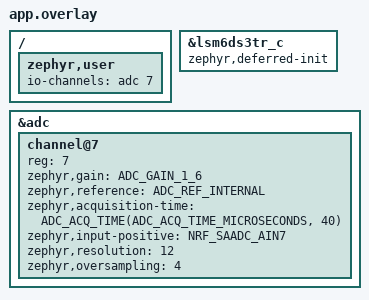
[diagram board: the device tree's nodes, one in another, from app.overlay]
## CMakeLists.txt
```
# Lift tracker D1 logger firmware
cmake_minimum_required(VERSION 3.20.0)
find_package(Zephyr REQUIRED HINTS $ENV{ZEPHYR_BASE})
project(lift_logger)

target_sources(app PRIVATE src/main.c src/storage.c src/ble.c)
```

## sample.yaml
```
sample:
  name: Lift tracker D1 logger
tests:
  lift.logger:
    platform_allow: xiao_ble/nrf52840/sense
    tags: sensors
```

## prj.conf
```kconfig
# ---- IMU: LSM6DS3TR-C (uses Zephyr's LSM6DSL driver) ----
CONFIG_SENSOR=y
CONFIG_LSM6DSL=y
CONFIG_LSM6DSL_TRIGGER_NONE=y
# 208 Hz output data rate for both sensors (the logger samples at 100 Hz)
CONFIG_LSM6DSL_ACCEL_ODR=5
CONFIG_LSM6DSL_GYRO_ODR=5
# +/-8 g and +/-1000 deg/s: headroom for fast reps without clipping
CONFIG_LSM6DSL_ACCEL_FS=8
CONFIG_LSM6DSL_GYRO_FS=1000

# ---- 2 MB external QSPI flash for recordings ----
CONFIG_FLASH=y

# ---- LEDs ----
CONFIG_GPIO=y

# ---- Shell + logs over the USB serial port ----
CONFIG_SHELL=y
CONFIG_SHELL_STACK_SIZE=4096
CONFIG_SHELL_CMD_BUFF_SIZE=128
CONFIG_LOG=y
CONFIG_MAIN_STACK_SIZE=2048
# Plain text output so the laptop script can parse it
CONFIG_SHELL_VT100_COLORS=n
CONFIG_CDC_ACM_SERIAL_PRODUCT_STRING="Lift Tracker Logger"

# ---- rec dfu: reboot into the UF2 bootloader ----
CONFIG_REBOOT=y

# ---- battery voltage (rec batt) ----
CONFIG_ADC=y

# ---- Bluetooth LE link to the phone app (src/ble.c) ----
CONFIG_BT=y
CONFIG_BT_PERIPHERAL=y
CONFIG_BT_DEVICE_NAME="LiftPod"
CONFIG_BT_MAX_CONN=1
# Ask the phone for a 15-30 ms connection interval: the live stream is 25 Hz
CONFIG_BT_PERIPHERAL_PREF_MIN_INT=12
CONFIG_BT_PERIPHERAL_PREF_MAX_INT=24
CONFIG_BT_PERIPHERAL_PREF_LATENCY=0
CONFIG_BT_PERIPHERAL_PREF_TIMEOUT=400
CONFIG_BT_GAP_AUTO_UPDATE_CONN_PARAMS=y
```

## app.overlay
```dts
/* The XIAO Sense powers its IMU through a GPIO-controlled switch
 * (lsm6ds3tr-c-en, 3 ms startup delay in the board file). The IMU can
 * need longer than that after power-up, and if Zephyr probes it too early
 * the driver gives up for good (device shows DISABLED). So skip the boot-time
 * init and start it from the firmware after a proper delay, with retries. */
&lsm6ds3tr_c {
	zephyr,deferred-init;
};

/* Battery voltage: the XIAO divides BAT through 1 M / 510 k onto P0.31
 * (AIN7). The divider's low side is P0.14, which the firmware drives low
 * to switch it on (and keeps low: Seeed warns against driving it high while
 * charging). */
/ {
	zephyr,user {
		io-channels = <&adc 7>;
	};
};

&adc {
	#address-cells = <1>;
	#size-cells = <0>;

	channel@7 {
		reg = <7>;
		zephyr,gain = "ADC_GAIN_1_6";
		zephyr,reference = "ADC_REF_INTERNAL";
		zephyr,acquisition-time = <ADC_ACQ_TIME(ADC_ACQ_TIME_MICROSECONDS, 40)>;
		zephyr,input-positive = <NRF_SAADC_AIN7>;   /* P0.31 */
		zephyr,resolution = <12>;
		zephyr,oversampling = <4>;
	};
};
```

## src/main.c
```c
/*
 * Lift tracker - D1 logger firmware (Seeed XIAO nRF52840 Sense)
 *
 * What it does
 *   - Reads the on-board IMU (LSM6DS3TR-C: accelerometer + gyroscope)
 *     at SAMPLE_HZ, all the time.
 *   - On battery (no USB cable): starts a recording automatically when you
 *     start moving, and stops after STOP_STILL_S seconds of stillness.
 *     So each set becomes its own recording, with no button to press.
 *     The last PRETRIGGER_S seconds before the motion are kept too, so the
 *     first rep is never cut off.
 *   - With the phone app (Bluetooth): the app starts and stops each set
 *     and labels it (exercise, weight, set number), and gets a live IMU
 *     stream for its rep counter. Once the app has connected, motion-
 *     triggered recording is off until the pod reboots, so walking
 *     between sets is never recorded. See ble.h.
 *   - On USB: never records by itself. A shell on the USB serial port lets
 *     the laptop list, dump (as CSV) and erase recordings, or start and
 *     stop a recording by hand for desk tests.
 *
 * LED
 *   green blink (fast)      recording
 *   green blip every 3 s    on battery, waiting for motion
 *   blue blip every 3 s     on battery, phone app connected
 *   blue                    on USB, idle
 *   red                     flash full, IMU missing or error (rec status / rec imu)
 *
 * Shell commands (open the serial port at any baud rate, press Enter)
 *   rec status | rec list | rec dump <id> | rec start | rec stop | rec erase | rec imu | rec batt | rec dfu
 *
 * Moving to the gym-pod PCB (BMI270 IMU, own flash and pins) only changes the
 * board overlay and read_imu(): storage, Bluetooth and the app stay as they are.
 */
#include <stdlib.h>
#include <zephyr/device.h>
#include <zephyr/drivers/adc.h>
#include <zephyr/drivers/gpio.h>
#include <zephyr/drivers/i2c.h>
#include <zephyr/drivers/sensor.h>
#include <zephyr/kernel.h>
#include <zephyr/logging/log.h>
#include <zephyr/shell/shell.h>
#include <zephyr/sys/reboot.h>
#include <zephyr/sys/util.h>
#include <hal/nrf_power.h>

#include "ble.h"
#include "storage.h"

LOG_MODULE_REGISTER(logger, LOG_LEVEL_INF);

/* ---- Tunable settings --------------------------------------------------
 * 100 Hz, not 200 Hz: rep motion has almost nothing above ~10 Hz, and at
 * 14 bytes per sample the 2 MB flash holds ~25 min of recording at 100 Hz
 * versus ~12 min at 200 Hz. The IMU itself runs at 208 Hz (prj.conf), so
 * every reading is fresh. */
#define SAMPLE_HZ        100
#define PRETRIGGER_S     2     /* seconds kept from before motion started */
#define START_MOVE_MS    300   /* this much movement starts a recording */
#define STOP_STILL_S     12    /* this much stillness ends it */
#define MAX_REC_S        300   /* safety cap: 5 minutes per recording */
#define FW_VERSION       2     /* shown in the app; 2 = Bluetooth + labels */

/* A sample counts as "moving" if either is true:
 *   gyro speed above MOVE_GYRO_DPS, or
 *   total acceleration more than MOVE_ACCEL_MG away from 1 g. */
#define MOVE_GYRO_DPS    40
#define MOVE_ACCEL_MG    150

#define PRE_SAMPLES      (PRETRIGGER_S * SAMPLE_HZ)
#define START_SAMPLES    (START_MOVE_MS * SAMPLE_HZ / 1000)
#define STOP_SAMPLES     (STOP_STILL_S * SAMPLE_HZ)
#define MAX_SAMPLES      (MAX_REC_S * SAMPLE_HZ)

/* ---- Hardware ---------------------------------------------------------- */
static const struct device *const imu = DEVICE_DT_GET(DT_NODELABEL(lsm6ds3tr_c));
static const struct device *const imu_bus = DEVICE_DT_GET(DT_NODELABEL(i2c0));
static const struct adc_dt_spec batt_adc = ADC_DT_SPEC_GET_BY_IDX(DT_PATH(zephyr_user), 0);
static const struct device *const gpio0 = DEVICE_DT_GET(DT_NODELABEL(gpio0));
#define VBAT_ENABLE_PIN  14    /* P0.14: low = battery divider on */
#define CHG_PIN          17    /* P0.17: BQ25101 ~CHG, low while charging */
static const struct gpio_dt_spec led_red = GPIO_DT_SPEC_GET(DT_ALIAS(led0), gpios);
static const struct gpio_dt_spec led_green = GPIO_DT_SPEC_GET(DT_ALIAS(led1), gpios);
static const struct gpio_dt_spec led_blue = GPIO_DT_SPEC_GET(DT_ALIAS(led2), gpios);

/* ---- Shared state (sampling thread <-> shell <-> LED loop) ------------- */
K_MUTEX_DEFINE(store_lock);          /* guards every storage_* call */

enum rec_mode { REC_AUTO, REC_MANUAL, REC_APP };

static volatile bool usb_power;       /* USB cable plugged in (VBUS present) */
static volatile bool fault;           /* flash full or write error */
static volatile bool imu_ok;          /* IMU started (see imu_start) */
static int imu_err = -EAGAIN;         /* last IMU start error */
static int imu_tries;                 /* attempts used to start the IMU */
static int imu_whoami = -1;           /* WHO_AM_I read straight off I2C */
static uint8_t imu_addr;              /* I2C address that answered */
static struct sample last_sample;     /* newest reading, for 'rec imu' */
static volatile bool manual_start_req;
static volatile bool manual_stop_req;
static enum rec_mode mode;
static uint32_t rec_len;              /* samples in the open recording */
static volatile bool auto_enabled = true; /* motion-triggered recording */
static volatile int batt_cache_mv;    /* refreshed every 10 s by main() */

/* Pre-trigger ring buffer: always holds the last PRE_SAMPLES samples. */
static struct sample ring[PRE_SAMPLES];
static uint32_t ring_head;            /* next slot to write */
static uint32_t ring_count;

static int16_t clamp16(int32_t v)
{
	return (int16_t)CLAMP(v, INT16_MIN, INT16_MAX);
}

/* Read one sample from the IMU, converted to milli-g and 0.1 deg/s. */
static int read_imu(struct sample *s)
{
	struct sensor_value a[3], g[3];
	int err = sensor_sample_fetch(imu);

	if (!err) {
		err = sensor_channel_get(imu, SENSOR_CHAN_ACCEL_XYZ, a);
	}
	if (!err) {
		err = sensor_channel_get(imu, SENSOR_CHAN_GYRO_XYZ, g);
	}
	if (err) {
		return err;
	}

	s->t_ms = (uint16_t)k_uptime_get_32();
	for (int i = 0; i < 3; i++) {
		s->a_mg[i] = clamp16(sensor_ms2_to_mg(&a[i]));
		/* rad/s -> units of 10 micro-degrees/s -> units of 0.1 deg/s */
		s->g_ddps[i] = clamp16(sensor_rad_to_10udegrees(&g[i]) / 10000);
	}
	return 0;
}

static bool is_moving(const struct sample *s)
{
	int32_t g2 = 0, a2 = 0;

	for (int i = 0; i < 3; i++) {
		g2 += (int32_t)s->g_ddps[i] * s->g_ddps[i];
		a2 += (int32_t)s->a_mg[i] * s->a_mg[i];
	}
	/* Compare squared magnitudes so no square root is needed. */
	const int32_t gyro_lim = MOVE_GYRO_DPS * 10;  /* in 0.1 deg/s */
	const int32_t lo = 1000 - MOVE_ACCEL_MG, hi = 1000 + MOVE_ACCEL_MG;

	return g2 > gyro_lim * gyro_lim || a2 < lo * lo || a2 > hi * hi;
}

static void ring_push(const struct sample *s)
{
	ring[ring_head] = *s;
	ring_head = (ring_head + 1) % PRE_SAMPLES;
	if (ring_count < PRE_SAMPLES) {
		ring_count++;
	}
}

/* Open a recording and copy the pre-trigger buffer into it, oldest first. */
static int start_recording(enum rec_mode m, const struct set_label *label)
{
	uint32_t pre = (m == REC_AUTO) ? ring_count : 0;
	int err;

	k_mutex_lock(&store_lock, K_FOREVER);
	err = storage_begin(SAMPLE_HZ, pre, label);
	if (!err) {
		uint32_t first = (ring_head + PRE_SAMPLES - ring_count) % PRE_SAMPLES;

		for (uint32_t i = 0; i < pre && !err; i++) {
			err = storage_append(&ring[(first + i) % PRE_SAMPLES]);
		}
	}
	k_mutex_unlock(&store_lock);

	if (err) {
		LOG_ERR("could not start recording (%d)", err);
		fault = true;
		return err;
	}
	mode = m;
	rec_len = pre;
	LOG_INF("recording started (%s)", m == REC_AUTO ? "auto" :
		m == REC_APP ? "app" : "manual");
	ble_status_changed();
	return 0;
}

static void stop_recording(void)
{
	k_mutex_lock(&store_lock, K_FOREVER);
	int err = storage_end();
	k_mutex_unlock(&store_lock);

	if (err) {
		fault = true;
	}
	ble_status_changed();
}

/* Write rep counts into recording `id` (0xFF = leave that one alone). */
static void set_reps(uint32_t id, uint8_t live, uint8_t confirmed)
{
	k_mutex_lock(&store_lock, K_FOREVER);
	int err = storage_set_reps(id, live, confirmed);
	k_mutex_unlock(&store_lock);

	if (err) {
		LOG_WRN("rec %u: could not store reps (%d)", id, err);
	}
}

/* Commands from the phone app. Runs in the sampling thread, so it never
 * races the recording logic. Returns the new "recording" state. */
static bool handle_app_cmds(bool recording)
{
	struct app_cmd c;

	while (ble_get_cmd(&c)) {
		switch (c.op) {
		case OP_START:
			if (recording) {         /* Start while recording: close it */
				stop_recording();
				recording = false;
			}
			if (!fault && start_recording(REC_APP, &c.label) == 0) {
				recording = true;
			}
			break;
		case OP_STOP:
			if (recording) {
				stop_recording();
				recording = false;
				k_mutex_lock(&store_lock, K_FOREVER);
				uint32_t n = storage_count();
				k_mutex_unlock(&store_lock);
				if (c.reps != 0xff && n > 0) {
					set_reps(n - 1, c.reps, 0xff);
				}
			}
			break;
		case OP_CONFIRM:
			set_reps(c.rec_id, 0xff, c.reps);
			break;
		case OP_AUTO:
			auto_enabled = c.on;
			LOG_INF("auto recording %s", c.on ? "on" : "off");
			break;
		}
		ble_status_changed();
	}
	return recording;
}

/* ---- IMU start-up -------------------------------------------------------
 * The IMU's boot-time init is deferred (app.overlay). Here: wait for it to
 * power up, read its ID straight off the I2C bus (so a dead or different
 * chip shows up in 'rec imu'), then start the driver, retrying a few times. */
static void imu_start(void)
{
	k_msleep(100);
	for (imu_tries = 1; imu_tries <= 10; imu_tries++) {
		uint8_t id;

		if (device_is_ready(imu_bus)) {
			if (i2c_reg_read_byte(imu_bus, 0x6A, 0x0F, &id) == 0) {
				imu_whoami = id; imu_addr = 0x6A;
			} else if (i2c_reg_read_byte(imu_bus, 0x6B, 0x0F, &id) == 0) {
				imu_whoami = id; imu_addr = 0x6B;
			}
		}
		imu_err = device_init(imu);
		if (imu_err == 0 || imu_err == -EALREADY) {
			imu_err = device_is_ready(imu) ? 0 : -ENODEV;
		}
		if (imu_err == 0) {
			imu_ok = true;
			LOG_INF("IMU started (try %d, id 0x%02x)", imu_tries, imu_whoami);
			return;
		}
		LOG_WRN("IMU start failed (%d), try %d", imu_err, imu_tries);
		k_msleep(200);
	}
	LOG_ERR("IMU did not start");
}

/* ---- Sampling thread --------------------------------------------------- */
K_TIMER_DEFINE(sample_timer, NULL, NULL);

static void sampling_thread(void)
{
	uint32_t move_score = 0;   /* leaky counter of recent movement */
	uint32_t still_run = 0;    /* consecutive still samples */

	imu_start();
	if (!imu_ok) {
		return;          /* LED goes red; 'rec imu' shows why */
	}

	k_timer_start(&sample_timer, K_USEC(1000000 / SAMPLE_HZ),
		      K_USEC(1000000 / SAMPLE_HZ));

	while (true) {
		k_timer_status_sync(&sample_timer);   /* wait for the next tick */

		struct sample s;

		if (read_imu(&s) != 0) {
			continue;
		}
		last_sample = s;
		bool moving = is_moving(&s);

		move_score = moving ? move_score + 1 : (move_score ? move_score - 1 : 0);
		still_run = moving ? 0 : still_run + 1;

		bool recording;

		k_mutex_lock(&store_lock, K_FOREVER);
		recording = storage_recording();
		k_mutex_unlock(&store_lock);

		if (manual_start_req) {
			manual_start_req = false;
			if (!recording && start_recording(REC_MANUAL, NULL) == 0) {
				recording = true;
			}
		}
		if (manual_stop_req) {
			manual_stop_req = false;
			if (recording) {
				stop_recording();
				recording = false;
			}
		}

		recording = handle_app_cmds(recording);
		ble_stream_sample(&s);

		if (recording) {
			k_mutex_lock(&store_lock, K_FOREVER);
			int err = storage_append(&s);
			k_mutex_unlock(&store_lock);
			rec_len++;

			bool auto_done = mode == REC_AUTO &&
					 (still_run >= STOP_SAMPLES || usb_power);
			/* Phone lost mid-set: end it like an auto recording would. */
			bool app_lost = mode == REC_APP && !ble_connected() &&
					still_run >= STOP_SAMPLES;

			if (err || auto_done || app_lost || rec_len >= MAX_SAMPLES) {
				if (err == -ENOSPC) {
					LOG_WRN("flash full");
				}
				fault = fault || err != 0;
				stop_recording();
				move_score = 0;
			}
		} else if (auto_enabled && !usb_power && !fault &&
			   move_score >= START_SAMPLES) {
			if (start_recording(REC_AUTO, NULL) == 0) {
				/* The sample that triggered it goes in right after
				 * the pre-trigger buffer. */
				k_mutex_lock(&store_lock, K_FOREVER);
				storage_append(&s);
				k_mutex_unlock(&store_lock);
				rec_len++;
				recording = true;
			}
			move_score = 0;
			still_run = 0;
		}

		/* Keep the pre-trigger buffer full while idle. */
		if (!recording) {
			ring_push(&s);
		} else {
			ring_count = 0;
		}
	}
}

K_THREAD_DEFINE(sampler, 2048, sampling_thread, NULL, NULL, NULL,
		K_PRIO_PREEMPT(2), 0, 1000);

/* ---- Battery ------------------------------------------------------------- */
static void batt_init(void)
{
	gpio_pin_configure(gpio0, VBAT_ENABLE_PIN, GPIO_OUTPUT_LOW);
	gpio_pin_configure(gpio0, CHG_PIN, GPIO_INPUT | GPIO_PULL_UP);
	adc_channel_setup_dt(&batt_adc);
}

/* Battery voltage in mV (BAT pad), or a negative error. */
static int batt_mv(void)
{
	int16_t raw;
	struct adc_sequence seq = { .buffer = &raw, .buffer_size = sizeof(raw) };
	int32_t mv;

	adc_sequence_init_dt(&batt_adc, &seq);
	if (adc_read_dt(&batt_adc, &seq) != 0) {
		return -EIO;
	}
	mv = raw;
	if (adc_raw_to_millivolts_dt(&batt_adc, &mv) != 0) {
		return -EIO;
	}
	return mv * 1510 / 510;      /* undo the 1 M / 510 k divider */
}

static bool charging(void)
{
	return gpio_pin_get(gpio0, CHG_PIN) == 0;
}

/* ---- Status for the phone app (ble.h) ----------------------------------- */
void pod_fill_status(struct pod_status *st)
{
	k_mutex_lock(&store_lock, K_FOREVER);
	bool rec = storage_recording();
	uint32_t n = storage_count();
	uint32_t used = storage_bytes_used(), total = storage_bytes_total();
	k_mutex_unlock(&store_lock);

	*st = (struct pod_status){
		.proto = POD_PROTO_VERSION,
		.flags = (rec ? ST_RECORDING : 0) | (usb_power ? ST_USB : 0) |
			 (usb_power && charging() ? ST_CHARGING : 0) |
			 (fault ? ST_FAULT : 0) | (imu_ok ? ST_IMU_OK : 0) |
			 (auto_enabled ? ST_AUTO : 0) |
			 (rec && mode == REC_APP ? ST_APP_REC : 0),
		.batt_mv = (uint16_t)MAX(batt_cache_mv, 0),
		.n_recs = (uint16_t)n,
		.last_rec = n ? (uint16_t)(n - 1) : 0xffff,
		.rec_samples = rec ? rec_len : 0,
		.flash_pct = (uint8_t)(used * 100ull / total),
		.fw = FW_VERSION,
		.rsvd = 0,
	};
}

/* ---- Shell commands ---------------------------------------------------- */
static int cmd_status(const struct shell *sh, size_t argc, char **argv)
{
	k_mutex_lock(&store_lock, K_FOREVER);
	bool rec = storage_recording();
	uint32_t n = storage_count();
	uint32_t used = storage_bytes_used(), total = storage_bytes_total();
	k_mutex_unlock(&store_lock);

	uint32_t free_s = (total - used) / sizeof(struct sample) / SAMPLE_HZ;

	shell_print(sh, "power:      %s", usb_power ? "USB" : "battery");
	shell_print(sh, "recording:  %s", rec ? "yes" : "no");
	shell_print(sh, "recordings: %u", n);
	shell_print(sh, "flash:      %u / %u KB used (~%u min left)",
		    used / 1024, total / 1024, free_s / 60);
	shell_print(sh, "fault:      %s", fault ? "YES (run 'rec erase' if full)" : "no");
	shell_print(sh, "imu:        %s", imu_ok ? "ok" : "NOT STARTED (run 'rec imu')");
	shell_print(sh, "app:        %s, auto recording %s", ble_connected() ? "connected" : "not connected",
		    auto_enabled ? "on" : "off");
	shell_print(sh, "firmware:   v%d", FW_VERSION);
	int mv = batt_mv();
	shell_print(sh, "battery:    %d.%02d V%s", mv / 1000, (mv % 1000) / 10,
		    usb_power ? (charging() ? " (charging)" : " (not charging: full or no battery)") : "");
	return 0;
}

static int cmd_batt(const struct shell *sh, size_t argc, char **argv)
{
	int mv = batt_mv();

	shell_print(sh, "battery:  %d mV  (full ~4200, empty ~3300; 0 or <2500 = not connected / cut off)", mv);
	shell_print(sh, "usb:      %s", usb_power ? "yes" : "no");
	shell_print(sh, "charging: %s", charging() ? "yes" : "no");
	return 0;
}

static int cmd_imu(const struct shell *sh, size_t argc, char **argv)
{
	shell_print(sh, "imu started: %s", imu_ok ? "yes" : "no");
	shell_print(sh, "start error: %d (tries %d)", imu_err, imu_tries);
	if (imu_whoami < 0) {
		shell_print(sh, "who_am_i:    no answer at I2C 0x6A or 0x6B");
	} else {
		shell_print(sh, "who_am_i:    0x%02x at I2C 0x%02x (LSM6DS3TR-C = 0x6a)",
			    imu_whoami, imu_addr);
	}
	if (imu_ok) {
		struct sample s = last_sample;

		shell_print(sh, "accel mg:    %d %d %d", s.a_mg[0], s.a_mg[1], s.a_mg[2]);
		shell_print(sh, "gyro 0.1dps: %d %d %d", s.g_ddps[0], s.g_ddps[1], s.g_ddps[2]);
	}
	return 0;
}

static int cmd_list(const struct shell *sh, size_t argc, char **argv)
{
	k_mutex_lock(&store_lock, K_FOREVER);
	uint32_t n = storage_count();

	/* Label columns are blank for unlabelled recordings. */
	shell_print(sh, "id,start_s,seconds,samples,pretrigger,exercise,day,set,warmup,"
		    "weight_kg,unix_time,session,reps_live,reps_confirmed,calibration");
	for (uint32_t i = 0; i < n; i++) {
		struct rec_info r;
		struct set_label l;
		struct set_result res;
		char lab[96] = ",,,,,,,,,";

		if (storage_get(i, &r) != 0) {
			continue;
		}
		uint32_t hz = r.sample_hz ? r.sample_hz : SAMPLE_HZ;

		if (storage_get_label(i, &l, &res) == 0 && l.exercise != LABEL_NONE) {
			char live[4] = "", conf[4] = "";

			if (res.reps_live != 0xff) {
				snprintk(live, sizeof(live), "%u", res.reps_live);
			}
			if (res.reps_confirmed != 0xff) {
				snprintk(conf, sizeof(conf), "%u", res.reps_confirmed);
			}
			snprintk(lab, sizeof(lab), "%u,%u,%u,%u,%u.%02u,%u,%u,%s,%s,%u",
				 l.exercise, l.day, l.set_no, (l.flags & LABEL_WARMUP) ? 1 : 0,
				 l.weight_cg / 100, l.weight_cg % 100, l.unix_time,
				 l.session_id, live, conf, (l.flags & LABEL_CALIB) ? 1 : 0);
		}
		shell_print(sh, "%u,%u,%u.%02u,%u,%u,%s", r.rec_id, r.start_uptime_s,
			    r.n_samples / hz, (r.n_samples % hz) * 100 / hz,
			    r.n_samples, r.pretrigger, lab);
	}
	k_mutex_unlock(&store_lock);
	return 0;
}

/* Prints one recording as CSV. The laptop script (python/tools/dump_logs.py)
 * reads everything between "#begin" and "#end". */
static int cmd_dump(const struct shell *sh, size_t argc, char **argv)
{
	uint32_t id = strtoul(argv[1], NULL, 10);
	struct rec_info r;

	k_mutex_lock(&store_lock, K_FOREVER);
	if (storage_recording()) {
		k_mutex_unlock(&store_lock);
		shell_error(sh, "stop the recording first (rec stop)");
		return -EBUSY;
	}
	if (storage_get(id, &r) != 0) {
		k_mutex_unlock(&store_lock);
		shell_error(sh, "no recording %u", id);
		return -ENOENT;
	}

	shell_print(sh, "#begin,%u,%u,%u,%u", r.rec_id, r.sample_hz, r.n_samples,
		    r.pretrigger);
	shell_print(sh, "i,t_ms,ax_mg,ay_mg,az_mg,gx_ddps,gy_ddps,gz_ddps");
	for (uint32_t i = 0; i < r.n_samples; i++) {
		struct sample s;

		if (storage_read_sample(&r, i, &s) != 0) {
			break;
		}
		shell_print(sh, "%u,%u,%d,%d,%d,%d,%d,%d", i, s.t_ms,
			    s.a_mg[0], s.a_mg[1], s.a_mg[2],
			    s.g_ddps[0], s.g_ddps[1], s.g_ddps[2]);
	}
	shell_print(sh, "#end,%u", r.rec_id);
	k_mutex_unlock(&store_lock);
	return 0;
}

static int cmd_start(const struct shell *sh, size_t argc, char **argv)
{
	manual_start_req = true;
	shell_print(sh, "starting a manual recording ('rec stop' to end it)");
	return 0;
}

static int cmd_stop(const struct shell *sh, size_t argc, char **argv)
{
	manual_stop_req = true;
	shell_print(sh, "stopping");
	return 0;
}

static int cmd_erase(const struct shell *sh, size_t argc, char **argv)
{
	shell_print(sh, "erasing all recordings (takes up to ~30 s)...");
	k_mutex_lock(&store_lock, K_FOREVER);
	int err = storage_erase_all();
	k_mutex_unlock(&store_lock);

	if (err) {
		shell_error(sh, "erase failed (%d)", err);
		return err;
	}
	fault = false;
	shell_print(sh, "done");
	return 0;
}

/* Reboot into the XIAO's UF2 bootloader (the XIAO-SENSE drive appears),
 * so new firmware can be copied on without double-tapping reset.
 * 0x57 in GPREGRET is the Adafruit nRF52 bootloader's "UF2 mode" magic. */
static int cmd_dfu(const struct shell *sh, size_t argc, char **argv)
{
	k_mutex_lock(&store_lock, K_FOREVER);
	if (storage_recording()) {
		storage_end();
	}
	k_mutex_unlock(&store_lock);
	shell_print(sh, "rebooting into the UF2 bootloader...");
	k_msleep(200);
	nrf_power_gpregret_set(NRF_POWER, 0, 0x57);
	sys_reboot(SYS_REBOOT_WARM);
	return 0;
}

SHELL_STATIC_SUBCMD_SET_CREATE(rec_cmds,
	SHELL_CMD(status, NULL, "Power, flash use and recording state", cmd_status),
	SHELL_CMD(list, NULL, "List recordings", cmd_list),
	SHELL_CMD_ARG(dump, NULL, "Print a recording as CSV: rec dump <id>", cmd_dump, 2, 0),
	SHELL_CMD(start, NULL, "Start a manual recording", cmd_start),
	SHELL_CMD(stop, NULL, "Stop the current recording", cmd_stop),
	SHELL_CMD(erase, NULL, "Erase ALL recordings", cmd_erase),
	SHELL_CMD(batt, NULL, "Battery voltage and charging state", cmd_batt),
	SHELL_CMD(dfu, NULL, "Reboot into the UF2 bootloader for a firmware update", cmd_dfu),
	SHELL_CMD(imu, NULL, "IMU start-up state, chip ID and one live reading", cmd_imu),
	SHELL_SUBCMD_SET_END);
SHELL_CMD_REGISTER(rec, &rec_cmds, "Lift tracker recordings", NULL);

/* ---- main: storage setup, then the LED loop ---------------------------- */
static void leds(bool r, bool g, bool b)
{
	gpio_pin_set_dt(&led_red, r);
	gpio_pin_set_dt(&led_green, g);
	gpio_pin_set_dt(&led_blue, b);
}

int main(void)
{
	gpio_pin_configure_dt(&led_red, GPIO_OUTPUT_INACTIVE);
	gpio_pin_configure_dt(&led_green, GPIO_OUTPUT_INACTIVE);
	gpio_pin_configure_dt(&led_blue, GPIO_OUTPUT_INACTIVE);
	batt_init();

	k_mutex_lock(&store_lock, K_FOREVER);
	if (storage_init() != 0) {
		fault = true;
	}
	k_mutex_unlock(&store_lock);
	batt_cache_mv = batt_mv();
	ble_init();

	for (uint32_t t = 0;; t++) {   /* one step every 100 ms */
		bool rec;

		k_mutex_lock(&store_lock, K_FOREVER);
		rec = storage_recording();
		k_mutex_unlock(&store_lock);
		if (t % 10 == 0) {    /* USB cable check, once a second */
			usb_power = nrf_power_usbregstatus_vbusdet_get(NRF_POWER);
		}
		if (t % 100 == 0) {   /* battery, every 10 s */
			batt_cache_mv = batt_mv();
		}

		if (fault || (!imu_ok && imu_tries > 10)) {
			leds(true, false, false);
		} else if (rec) {
			leds(false, t % 5 == 0, false);       /* fast green blink */
		} else if (usb_power) {
			leds(false, false, true);             /* blue: on USB */
		} else if (ble_connected()) {
			leds(false, false, t % 30 == 0);      /* blue blip: app */
		} else {
			leds(false, t % 30 == 0, false);      /* blip every 3 s */
		}
		k_sleep(K_MSEC(100));
	}
	return 0;
}
```

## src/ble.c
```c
/*
 * ble.c - "Lift Pod" GATT service. See ble.h for the protocol.
 *
 * Writes from the phone land in a queue that the sampling thread drains,
 * so recordings are only ever started and stopped from one thread.
 * Notifications go out from a low-priority thread of their own, so a slow
 * radio link can never delay the 100 Hz sampling.
 */
#include "ble.h"

#include <string.h>
#include <zephyr/bluetooth/bluetooth.h>
#include <zephyr/bluetooth/conn.h>
#include <zephyr/bluetooth/gatt.h>
#include <zephyr/bluetooth/uuid.h>
#include <zephyr/kernel.h>
#include <zephyr/logging/log.h>

LOG_MODULE_REGISTER(ble, LOG_LEVEL_INF);

#define LT_UUID(n) BT_UUID_128_ENCODE(0x4c540000 + (n), 0x7c3e, 0x4f6b, 0x9a1e, 0x5f2b6c0d4e11)

static const struct bt_uuid_128 svc_uuid = BT_UUID_INIT_128(LT_UUID(1));
static const struct bt_uuid_128 ctrl_uuid = BT_UUID_INIT_128(LT_UUID(2));
static const struct bt_uuid_128 status_uuid = BT_UUID_INIT_128(LT_UUID(3));
static const struct bt_uuid_128 stream_uuid = BT_UUID_INIT_128(LT_UUID(4));

K_MSGQ_DEFINE(cmd_q, sizeof(struct app_cmd), 8, 4);
K_MSGQ_DEFINE(stream_q, sizeof(struct stream_pkt), 16, 2);
K_SEM_DEFINE(status_sem, 0, 1);

static struct bt_conn *conn;
static struct k_spinlock conn_lock;   /* conn is set/cleared by the BT host */
static volatile bool status_on, stream_on;
static uint16_t stream_seq;
static uint32_t stream_div;

/* ---- Control: writes from the app ---------------------------------------- */
static ssize_t ctrl_write(struct bt_conn *c, const struct bt_gatt_attr *attr,
			  const void *buf, uint16_t len, uint16_t offset, uint8_t flags)
{
	const uint8_t *p = buf;
	struct app_cmd cmd = { 0 };

	if (offset != 0 || len < 1) {
		return BT_GATT_ERR(BT_ATT_ERR_INVALID_ATTRIBUTE_LEN);
	}
	cmd.op = p[0];
	switch (p[0]) {
	case OP_START: {
		struct op_start s;

		if (len < sizeof(s)) {
			return BT_GATT_ERR(BT_ATT_ERR_INVALID_ATTRIBUTE_LEN);
		}
		memcpy(&s, p, sizeof(s));
		cmd.label = (struct set_label){
			.unix_time = s.unix_time,
			.session_id = s.session_id,
			.weight_cg = s.weight_cg,
			.exercise = s.exercise,
			.day = s.day,
			.set_no = s.set_no,
			.flags = (s.flags & (LABEL_WARMUP | LABEL_CALIB)) | LABEL_FROM_APP,
			.rsvd = 0xffff,
		};
		break;
	}
	case OP_STOP:
		cmd.reps = len >= 2 ? p[1] : 0xff;
		break;
	case OP_CONFIRM:
		if (len < 4) {
			return BT_GATT_ERR(BT_ATT_ERR_INVALID_ATTRIBUTE_LEN);
		}
		cmd.rec_id = p[1] | (p[2] << 8);
		cmd.reps = p[3];
		break;
	case OP_AUTO:
		if (len < 2) {
			return BT_GATT_ERR(BT_ATT_ERR_INVALID_ATTRIBUTE_LEN);
		}
		cmd.on = p[1] != 0;
		break;
	default:
		return BT_GATT_ERR(BT_ATT_ERR_NOT_SUPPORTED);
	}
	if (k_msgq_put(&cmd_q, &cmd, K_NO_WAIT) != 0) {
		return BT_GATT_ERR(BT_ATT_ERR_PREPARE_QUEUE_FULL);
	}
	return len;
}

/* ---- Status: read or notify ----------------------------------------------- */
static ssize_t status_read(struct bt_conn *c, const struct bt_gatt_attr *attr,
			   void *buf, uint16_t len, uint16_t offset)
{
	struct pod_status st;

	pod_fill_status(&st);
	return bt_gatt_attr_read(c, attr, buf, len, offset, &st, sizeof(st));
}

static void status_ccc(const struct bt_gatt_attr *attr, uint16_t value)
{
	status_on = value == BT_GATT_CCC_NOTIFY;
	ble_status_changed();
}

static void stream_ccc(const struct bt_gatt_attr *attr, uint16_t value)
{
	stream_on = value == BT_GATT_CCC_NOTIFY;
}

/* attrs: 0 service | 1,2 control | 3,4,5 status (+CCC) | 6,7,8 stream (+CCC) */
BT_GATT_SERVICE_DEFINE(pod_svc,
	BT_GATT_PRIMARY_SERVICE(&svc_uuid),
	BT_GATT_CHARACTERISTIC(&ctrl_uuid.uuid,
			       BT_GATT_CHRC_WRITE | BT_GATT_CHRC_WRITE_WITHOUT_RESP,
			       BT_GATT_PERM_WRITE, NULL, ctrl_write, NULL),
	BT_GATT_CHARACTERISTIC(&status_uuid.uuid,
			       BT_GATT_CHRC_READ | BT_GATT_CHRC_NOTIFY,
			       BT_GATT_PERM_READ, status_read, NULL, NULL),
	BT_GATT_CCC(status_ccc, BT_GATT_PERM_READ | BT_GATT_PERM_WRITE),
	BT_GATT_CHARACTERISTIC(&stream_uuid.uuid, BT_GATT_CHRC_NOTIFY,
			       BT_GATT_PERM_NONE, NULL, NULL, NULL),
	BT_GATT_CCC(stream_ccc, BT_GATT_PERM_READ | BT_GATT_PERM_WRITE),
);

/* ---- Advertising and connections ------------------------------------------ */
static const struct bt_data ad[] = {
	BT_DATA_BYTES(BT_DATA_FLAGS, (BT_LE_AD_GENERAL | BT_LE_AD_NO_BREDR)),
	BT_DATA_BYTES(BT_DATA_UUID128_ALL, LT_UUID(1)),
};

static const struct bt_data sd[] = {
	BT_DATA(BT_DATA_NAME_COMPLETE, CONFIG_BT_DEVICE_NAME,
		sizeof(CONFIG_BT_DEVICE_NAME) - 1),
};

static void adv_start(struct k_work *w)
{
	int err = bt_le_adv_start(BT_LE_ADV_CONN_FAST_2, ad, ARRAY_SIZE(ad),
				  sd, ARRAY_SIZE(sd));

	if (err && err != -EALREADY) {
		LOG_ERR("advertising failed (%d)", err);
	}
}
K_WORK_DEFINE(adv_work, adv_start);

static void on_connected(struct bt_conn *c, uint8_t err)
{
	if (err) {
		return;
	}
	k_spinlock_key_t key = k_spin_lock(&conn_lock);

	conn = bt_conn_ref(c);
	k_spin_unlock(&conn_lock, key);
	LOG_INF("app connected");
	/* The app is in charge now: no more motion-triggered recordings
	 * (walking between sets) until it says otherwise or the pod reboots. */
	struct app_cmd cmd = { .op = OP_AUTO, .on = 0 };

	k_msgq_put(&cmd_q, &cmd, K_NO_WAIT);
}

static void on_disconnected(struct bt_conn *c, uint8_t reason)
{
	LOG_INF("app disconnected (0x%02x)", reason);
	k_spinlock_key_t key = k_spin_lock(&conn_lock);
	struct bt_conn *old = conn;

	conn = NULL;
	status_on = stream_on = false;
	k_spin_unlock(&conn_lock, key);
	if (old) {
		bt_conn_unref(old);
	}
}

static void on_recycled(void)
{
	k_work_submit(&adv_work);   /* the connection object is free again */
}

BT_CONN_CB_DEFINE(conn_cbs) = {
	.connected = on_connected,
	.disconnected = on_disconnected,
	.recycled = on_recycled,
};

/* ---- Public API ------------------------------------------------------------ */
bool ble_connected(void)
{
	return conn != NULL;
}

bool ble_get_cmd(struct app_cmd *out)
{
	return k_msgq_get(&cmd_q, out, K_NO_WAIT) == 0;
}

void ble_stream_sample(const struct sample *s)
{
	if (!stream_on || ++stream_div < 4) {
		return;
	}
	stream_div = 0;

	struct stream_pkt p = { .seq = stream_seq++ };

	memcpy(p.a_mg, s->a_mg, sizeof(p.a_mg));
	memcpy(p.g_ddps, s->g_ddps, sizeof(p.g_ddps));
	k_msgq_put(&stream_q, &p, K_NO_WAIT);   /* dropped if the radio is behind */
}

void ble_status_changed(void)
{
	k_sem_give(&status_sem);
}

/* A reference to the current connection, or NULL. Unref when done. */
static struct bt_conn *conn_get(void)
{
	k_spinlock_key_t key = k_spin_lock(&conn_lock);
	struct bt_conn *c = conn ? bt_conn_ref(conn) : NULL;

	k_spin_unlock(&conn_lock, key);
	return c;
}

static void ble_thread(void)
{
	int64_t next_status = 0;

	while (true) {
		struct stream_pkt p;

		/* Wake for a stream packet, a status poke, or every 100 ms. */
		bool got = k_msgq_get(&stream_q, &p, K_MSEC(100)) == 0;
		bool poke = k_sem_take(&status_sem, K_NO_WAIT) == 0;
		struct bt_conn *c = conn_get();

		if (!c) {
			continue;
		}
		if (got && stream_on) {
			bt_gatt_notify(c, &pod_svc.attrs[7], &p, sizeof(p));
		}
		if ((poke || k_uptime_get() >= next_status) && status_on) {
			struct pod_status st;

			pod_fill_status(&st);
			bt_gatt_notify(c, &pod_svc.attrs[4], &st, sizeof(st));
			next_status = k_uptime_get() + 1000;
		}
		bt_conn_unref(c);
	}
}

K_THREAD_DEFINE(ble_tx, 1536, ble_thread, NULL, NULL, NULL,
		K_PRIO_PREEMPT(8), 0, 2000);

int ble_init(void)
{
	int err = bt_enable(NULL);

	if (err) {
		LOG_ERR("bluetooth init failed (%d)", err);
		return err;
	}
	k_work_submit(&adv_work);
	LOG_INF("advertising as \"%s\"", CONFIG_BT_DEVICE_NAME);
	return 0;
}
```

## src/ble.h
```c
/*
 * ble.h - Bluetooth LE link to the phone app.
 *
 * One GATT service, "Lift Pod", with three characteristics. All values are
 * little-endian. The phone app (app/android) is the only client.
 *
 *   Control  (write)   commands from the app: start/stop a labelled set,
 *                      confirm the rep count, auto-recording on/off
 *   Status   (read, notify ~1/s)  struct pod_status
 *   Stream   (notify)  live IMU at STREAM_HZ while the app listens:
 *                      struct stream_pkt, used for the live rep count
 *
 * UUIDs: 4c54000N-7c3e-4f6b-9a1e-5f2b6c0d4e11, N = 1 service, 2 control,
 * 3 status, 4 stream. Keep them in sync with app/android (PodProtocol.kt).
 */
#ifndef BLE_H_
#define BLE_H_

#include <stdbool.h>
#include <stdint.h>
#include "storage.h"

#define POD_PROTO_VERSION 1
#define STREAM_HZ         25     /* SAMPLE_HZ / 4 */

/* Control opcodes (first byte of every write). */
enum pod_op {
	OP_START   = 0x01,  /* struct op_start: begin a labelled recording */
	OP_STOP    = 0x02,  /* [op][reps_live]: end it (reps 0xFF = unknown) */
	OP_CONFIRM = 0x03,  /* [op][rec_id u16][reps]: rep count you confirmed */
	OP_AUTO    = 0x04,  /* [op][0|1]: motion-triggered recording off/on */
};

struct __packed op_start {
	uint8_t op;            /* OP_START */
	uint8_t exercise;
	uint8_t day;
	uint8_t set_no;
	uint8_t flags;         /* LABEL_WARMUP | LABEL_CALIB */
	uint16_t weight_cg;    /* 0.01 kg */
	uint32_t unix_time;
	uint32_t session_id;
};                             /* 15 bytes */

/* Status flags */
#define ST_RECORDING  BIT(0)
#define ST_USB        BIT(1)
#define ST_CHARGING   BIT(2)
#define ST_FAULT      BIT(3)
#define ST_IMU_OK     BIT(4)
#define ST_AUTO       BIT(5)   /* motion-triggered recording is on */
#define ST_APP_REC    BIT(6)   /* the open recording was started by the app */

struct __packed pod_status {
	uint8_t proto;         /* POD_PROTO_VERSION */
	uint8_t flags;         /* ST_* */
	uint16_t batt_mv;
	uint16_t n_recs;       /* recordings on flash */
	uint16_t last_rec;     /* id of the newest finished recording, 0xFFFF none */
	uint32_t rec_samples;  /* samples in the open recording */
	uint8_t flash_pct;     /* flash used, % */
	uint8_t fw;            /* firmware version */
	uint16_t rsvd;
};                             /* 16 bytes */

struct __packed stream_pkt {
	uint16_t seq;          /* +1 per packet: spots dropped packets */
	int16_t a_mg[3];
	int16_t g_ddps[3];
};                             /* 14 bytes */

/* A command from the app, handed to the sampling thread. */
struct app_cmd {
	uint8_t op;
	uint8_t reps;
	uint8_t on;
	uint16_t rec_id;
	struct set_label label;
};

int ble_init(void);
bool ble_connected(void);

/* Non-blocking: true and *out filled if the app sent a command. */
bool ble_get_cmd(struct app_cmd *out);

/* Call for every IMU sample (SAMPLE_HZ). Sends every 4th one if the app is
 * listening. Never blocks. */
void ble_stream_sample(const struct sample *s);

/* Ask for a status notification now (e.g. a recording just started). */
void ble_status_changed(void);

/* Implemented in main.c: current state for the Status characteristic. */
void pod_fill_status(struct pod_status *st);

#endif /* BLE_H_ */
```

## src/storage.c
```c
/*
 * storage.c - append-only recording log on the external QSPI NOR flash.
 * See storage.h for the on-flash layout.
 */
#include "storage.h"

#include <errno.h>
#include <string.h>
#include <zephyr/device.h>
#include <zephyr/drivers/flash.h>
#include <zephyr/kernel.h>
#include <zephyr/logging/log.h>

LOG_MODULE_REGISTER(storage, LOG_LEVEL_INF);

#define FLASH_NODE  DT_NODELABEL(p25q16h)
#define FLASH_SIZE  (DT_PROP(FLASH_NODE, size) / 8)  /* DT size is in bits */
#define PAGE_SIZE   256u
#define MAX_RECS    512u

BUILD_ASSERT(sizeof(struct rec_header) == 64, "header must be 64 bytes");
BUILD_ASSERT(offsetof(struct rec_header, result) % 4 == 0,
	     "QSPI writes must be 4-byte aligned");
BUILD_ASSERT(sizeof(struct sample) == 14, "sample must be 14 bytes");
BUILD_ASSERT(offsetof(struct rec_header, n_samples) % 4 == 0,
	     "QSPI writes must be 4-byte aligned");

static const struct device *const flash = DEVICE_DT_GET(FLASH_NODE);

static struct rec_info recs[MAX_RECS];
static uint32_t n_recs;
static uint32_t next_free;        /* page-aligned address for the next header */

/* The open recording, if any. Samples are collected into a page-sized
 * buffer and written one full page at a time. */
static bool open;
static uint32_t write_addr;       /* page-aligned address of page_buf */
static uint32_t open_samples;
static uint8_t __aligned(4) page_buf[PAGE_SIZE];
static uint32_t page_fill;

static uint32_t align_up(uint32_t x, uint32_t a)
{
	return (x + a - 1) / a * a;
}

static bool all_ff(const uint8_t *p, size_t n)
{
	for (size_t i = 0; i < n; i++) {
		if (p[i] != 0xff) {
			return false;
		}
	}
	return true;
}

/* A recording that never got its count written (power was lost mid-set).
 * Samples reach flash only as whole 256-byte pages, so the data ends at the
 * first completely blank page. Count only the samples that fit entirely
 * before it: the last one may have been cut in half by the page boundary. */
static uint32_t recover_count(uint32_t hdr_addr, uint32_t hdr_size)
{
	static uint8_t __aligned(4) page[PAGE_SIZE];
	uint32_t end = hdr_addr;

	while (end + PAGE_SIZE <= FLASH_SIZE) {
		if (flash_read(flash, end, page, PAGE_SIZE) != 0 ||
		    all_ff(page, PAGE_SIZE)) {
			break;
		}
		/* Stop at the next recording's header too. */
		uint32_t first_word;

		memcpy(&first_word, page, sizeof(first_word));
		if (end != hdr_addr && first_word == REC_MAGIC) {
			break;
		}
		end += PAGE_SIZE;
	}

	uint32_t data_start = hdr_addr + hdr_size;

	return end > data_start ? (end - data_start) / sizeof(struct sample) : 0;
}

int storage_init(void)
{
	if (!device_is_ready(flash)) {
		LOG_ERR("QSPI flash not ready");
		return -ENODEV;
	}

	n_recs = 0;
	next_free = 0;
	open = false;
	page_fill = 0;

	while (next_free + PAGE_SIZE <= FLASH_SIZE && n_recs < MAX_RECS) {
		struct rec_header h;

		if (flash_read(flash, next_free, &h, sizeof(h)) != 0) {
			return -EIO;
		}
		if (h.magic != REC_MAGIC) {
			break;  /* blank flash: this is where the next one goes */
		}

		uint32_t n = h.n_samples;
		uint32_t hs = h.version >= 2 ? h.header_size : REC_HEADER_V1_SIZE;

		if (hs < REC_HEADER_V1_SIZE || hs > PAGE_SIZE) {
			hs = REC_HEADER_V1_SIZE;
		}
		if (n == REC_UNFINISHED) {
			n = recover_count(next_free, hs);
			LOG_WRN("rec %u was not closed, recovered %u samples",
				h.rec_id, n);
			/* Write the count now so this repair only happens once. */
			uint32_t __aligned(4) count = n;

			flash_write(flash, next_free + offsetof(struct rec_header, n_samples),
				    &count, sizeof(count));
		}

		recs[n_recs] = (struct rec_info){
			.rec_id = h.rec_id,
			.addr = next_free,
			.n_samples = n,
			.start_uptime_s = h.start_uptime_s,
			.sample_hz = h.sample_hz,
			.header_size = hs,
			.pretrigger = h.pretrigger,
		};
		n_recs++;
		next_free = align_up(next_free + hs + n * sizeof(struct sample),
				     PAGE_SIZE);
	}

	LOG_INF("%u recordings, %u of %u bytes used", n_recs, next_free,
		(uint32_t)FLASH_SIZE);
	return 0;
}

static int flush_page(void)
{
	if (page_fill == 0) {
		return 0;
	}
	/* The unused tail of the page stays 0xFF, which reads as "blank". */
	memset(page_buf + page_fill, 0xff, PAGE_SIZE - page_fill);
	int err = flash_write(flash, write_addr, page_buf, PAGE_SIZE);

	if (err) {
		LOG_ERR("flash write failed at 0x%06x (%d)", write_addr, err);
	}
	return err;
}

int storage_begin(uint16_t sample_hz, uint32_t pretrigger,
		  const struct set_label *label)
{
	if (open) {
		return -EALREADY;
	}
	if (n_recs >= MAX_RECS || next_free + 2 * PAGE_SIZE > FLASH_SIZE) {
		return -ENOSPC;
	}

	/* Flash can only be written where it has been erased. Check the first
	 * page is blank, so a never-erased chip gives a clear error instead of
	 * silently corrupted recordings. Run "rec erase" once to fix. */
	static uint8_t __aligned(4) probe[PAGE_SIZE];

	if (flash_read(flash, next_free, probe, sizeof(probe)) != 0) {
		return -EIO;
	}
	if (!all_ff(probe, sizeof(probe))) {
		LOG_ERR("flash not erased at 0x%06x: run 'rec erase'", next_free);
		return -EIO;
	}

	struct rec_header h;

	memset(&h, 0xff, sizeof(h));
	h = (struct rec_header){
		.magic = REC_MAGIC,
		.version = REC_VERSION,
		.header_size = sizeof(struct rec_header),
		.rec_id = n_recs,
		.sample_hz = sample_hz,
		.sample_size = sizeof(struct sample),
		.start_uptime_s = (uint32_t)(k_uptime_get() / 1000),
		.pretrigger = pretrigger,
		.n_samples = REC_UNFINISHED,
		.reserved = 0xffffffff,
		.result = { 0xff, 0xff, 0xffff },
		.rsvd2 = { 0xffffffff, 0xffffffff, 0xffffffff },
	};
	if (label) {
		h.label = *label;
	} else {
		memset(&h.label, 0xff, sizeof(h.label));
	}

	/* The header goes into the first page buffer with the first samples. */
	memset(page_buf, 0xff, sizeof(page_buf));
	memcpy(page_buf, &h, sizeof(h));
	page_fill = sizeof(h);
	write_addr = next_free;
	open_samples = 0;
	open = true;
	return 0;
}

int storage_append(const struct sample *s)
{
	if (!open) {
		return -EINVAL;
	}

	/* Never let a sample run past the end of the chip. */
	if (write_addr + page_fill + sizeof(*s) > FLASH_SIZE) {
		return -ENOSPC;
	}

	const uint8_t *src = (const uint8_t *)s;
	size_t left = sizeof(*s);

	/* A 14-byte sample may straddle two pages. */
	while (left > 0) {
		size_t room = PAGE_SIZE - page_fill;
		size_t n = MIN(room, left);

		memcpy(page_buf + page_fill, src, n);
		page_fill += n;
		src += n;
		left -= n;

		if (page_fill == PAGE_SIZE) {
			int err = flush_page();

			if (err) {
				return err;
			}
			write_addr += PAGE_SIZE;
			page_fill = 0;
		}
	}
	open_samples++;
	return 0;
}

int storage_end(void)
{
	if (!open) {
		return -EINVAL;
	}

	uint32_t hdr_addr = next_free;
	int err = flush_page();

	/* Program the real sample count into the header (0xFF -> value). */
	uint32_t __aligned(4) count = open_samples;

	if (!err) {
		err = flash_write(flash, hdr_addr + offsetof(struct rec_header, n_samples),
				  &count, sizeof(count));
	}

	recs[n_recs] = (struct rec_info){
		.rec_id = n_recs,
		.addr = hdr_addr,
		.n_samples = open_samples,
		.start_uptime_s = 0,
		.sample_hz = 0,
		.header_size = sizeof(struct rec_header),
		.pretrigger = 0,
	};
	/* Re-read the header so the RAM table matches what's on flash. */
	struct rec_header h;

	if (flash_read(flash, hdr_addr, &h, sizeof(h)) == 0) {
		recs[n_recs].start_uptime_s = h.start_uptime_s;
		recs[n_recs].sample_hz = h.sample_hz;
		recs[n_recs].pretrigger = h.pretrigger;
	}
	n_recs++;
	next_free = align_up(hdr_addr + sizeof(struct rec_header) +
			     open_samples * sizeof(struct sample), PAGE_SIZE);
	open = false;
	page_fill = 0;

	LOG_INF("rec %u closed: %u samples", n_recs - 1, open_samples);
	return err;
}

bool storage_recording(void)
{
	return open;
}

uint32_t storage_count(void)
{
	return n_recs;
}

int storage_get(uint32_t index, struct rec_info *out)
{
	if (index >= n_recs) {
		return -ENOENT;
	}
	*out = recs[index];
	return 0;
}

int storage_read_sample(const struct rec_info *rec, uint32_t i,
			struct sample *out)
{
	if (i >= rec->n_samples) {
		return -EINVAL;
	}
	return flash_read(flash, rec->addr + rec->header_size +
			  i * sizeof(struct sample), out, sizeof(*out));
}

int storage_get_label(uint32_t index, struct set_label *label,
		      struct set_result *result)
{
	memset(label, 0xff, sizeof(*label));
	memset(result, 0xff, sizeof(*result));
	if (index >= n_recs) {
		return -ENOENT;
	}
	if (recs[index].header_size < sizeof(struct rec_header)) {
		return 0;    /* version 1: no label */
	}
	struct rec_header h;
	int err = flash_read(flash, recs[index].addr, &h, sizeof(h));

	if (!err) {
		*label = h.label;
		*result = h.result;
	}
	return err;
}

int storage_set_reps(uint32_t index, uint8_t reps_live, uint8_t reps_confirmed)
{
	struct set_label l;
	struct set_result r;
	int err;

	if (index >= n_recs) {
		return -ENOENT;
	}
	if (recs[index].header_size < sizeof(struct rec_header)) {
		return -ENOTSUP;
	}
	err = storage_get_label(index, &l, &r);
	if (err) {
		return err;
	}
	if ((reps_live != 0xff && r.reps_live != 0xff && r.reps_live != reps_live) ||
	    (reps_confirmed != 0xff && r.reps_confirmed != 0xff &&
	     r.reps_confirmed != reps_confirmed)) {
		return -EALREADY;   /* NOR flash: a written byte can't be rewritten */
	}
	struct set_result __aligned(4) w = { reps_live, reps_confirmed, 0xffff };

	return flash_write(flash, recs[index].addr + offsetof(struct rec_header, result),
			   &w, sizeof(w));
}

uint32_t storage_bytes_used(void)
{
	return open ? write_addr + page_fill : next_free;
}

uint32_t storage_bytes_total(void)
{
	return FLASH_SIZE;
}

int storage_erase_all(void)
{
	if (open) {
		return -EBUSY;
	}
	int err = flash_erase(flash, 0, FLASH_SIZE);

	if (!err) {
		n_recs = 0;
		next_free = 0;
	}
	return err;
}
```
